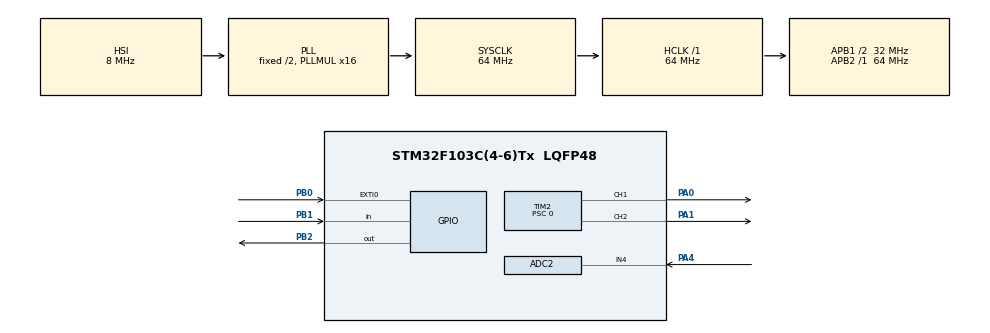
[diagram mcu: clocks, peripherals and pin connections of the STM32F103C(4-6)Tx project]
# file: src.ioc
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ADC1.Channel-2\#ChannelRegularConversion=ADC_CHANNEL_VREFINT
ADC1.ContinuousConvMode=DISABLE
ADC1.DiscontinuousConvMode=DISABLE
ADC1.EnableRegularConversion=ENABLE
ADC1.NbrOfConversion=1
ADC1.NbrOfConversionFlag=1
ADC1.Rank-2\#ChannelRegularConversion=1
ADC1.SamplingTime-2\#ChannelRegularConversion=ADC_SAMPLETIME_7CYCLES_5
ADC1.master=1
ADC2.Channel-1\#ChannelRegularConversion=ADC_CHANNEL_4
ADC2.NbrOfConversionFlag=1
ADC2.Rank-1\#ChannelRegularConversion=1
ADC2.SamplingTime-1\#ChannelRegularConversion=ADC_SAMPLETIME_13CYCLES_5
Dma.Request0=TIM2_CH1
Dma.Request1=TIM2_CH2/CH4
Dma.TIM2_CH1.0.Direction=DMA_MEMORY_TO_PERIPH
Dma.TIM2_CH1.0.Instance=DMA1_Channel5
Dma.TIM2_CH1.0.MemDataAlignment=DMA_MDATAALIGN_WORD
Dma.TIM2_CH1.0.MemInc=DMA_MINC_ENABLE
Dma.TIM2_CH1.0.Mode=DMA_NORMAL
Dma.TIM2_CH1.0.PeriphDataAlignment=DMA_PDATAALIGN_WORD
Dma.TIM2_CH1.0.PeriphInc=DMA_PINC_DISABLE
Dma.TIM2_CH1.0.Priority=DMA_PRIORITY_LOW
Dma.TIM2_CH2/CH4.1.Direction=DMA_MEMORY_TO_PERIPH
Dma.TIM2_CH2/CH4.1.Instance=DMA1_Channel7
Dma.TIM2_CH2/CH4.1.MemDataAlignment=DMA_MDATAALIGN_WORD
Dma.TIM2_CH2/CH4.1.MemInc=DMA_MINC_ENABLE
Dma.TIM2_CH2/CH4.1.Mode=DMA_NORMAL
Dma.TIM2_CH2/CH4.1.PeriphDataAlignment=DMA_PDATAALIGN_WORD
Dma.TIM2_CH2/CH4.1.PeriphInc=DMA_PINC_DISABLE
Dma.TIM2_CH2/CH4.1.Priority=DMA_PRIORITY_LOW
Mcu.Family=STM32F1
Mcu.Name=STM32F103C(4-6)Tx
Mcu.Package=LQFP48
NVIC.DMA1_Channel5_IRQn=true\:0\:0\:false\:false\:true\:false\:true\:true
NVIC.DMA1_Channel7_IRQn=true\:0\:0\:false\:false\:true\:false\:true\:true
NVIC.EXTI0_IRQn=true\:1\:0\:true\:false\:true\:true\:true\:true
NVIC.PriorityGroup=NVIC_PRIORITYGROUP_4
NVIC.TIM1_UP_IRQn=true\:2\:0\:true\:false\:true\:true\:true\:true
NVIC.TIM3_IRQn=true\:0\:0\:false\:false\:true\:true\:true\:true
PA0-WKUP.Signal=S_TIM2_CH1_ETR
PA1.Signal=S_TIM2_CH2
PA13.Mode=Serial_Wire
PA13.Signal=SYS_JTMS-SWDIO
PA14.Mode=Serial_Wire
PA14.Signal=SYS_JTCK-SWCLK
PA4.Signal=ADCx_IN4
PB0.GPIO_ModeDefaultEXTI=GPIO_MODE_IT_RISING_FALLING
PB0.GPIO_PuPd=GPIO_PULLUP
PB0.Signal=GPXTI0
PB1.Signal=GPIO_Input
PB2.Signal=GPIO_Output
PD0-OSC_IN.Mode=HSE-External-Oscillator
PD0-OSC_IN.Signal=RCC_OSC_IN
PD1-OSC_OUT.Mode=HSE-External-Oscillator
PD1-OSC_OUT.Signal=RCC_OSC_OUT
ProjectManager.HeapSize=0x200
ProjectManager.StackSize=0x400
ProjectManager.TargetToolchain=CMake
RCC.ADCPresc=RCC_ADCPCLK2_DIV8
RCC.AHBFreq_Value=64000000
RCC.APB1CLKDivider=RCC_HCLK_DIV2
RCC.APB1Freq_Value=32000000
RCC.APB1TimFreq_Value=64000000
RCC.APB2Freq_Value=64000000
RCC.APB2TimFreq_Value=64000000
RCC.HCLKFreq_Value=64000000
RCC.PLLMUL=RCC_PLL_MUL16
RCC.SYSCLKFreq_VALUE=64000000
RCC.SYSCLKSource=RCC_SYSCLKSOURCE_PLLCLK
RCC.USBFreq_Value=64000000
SH.ADCx_IN4.0=ADC2_IN4,IN4
SH.S_TIM2_CH1_ETR.0=TIM2_CH1,PWM Generation1 CH1
SH.S_TIM2_CH2.0=TIM2_CH2,PWM Generation2 CH2
TIM1.Period=1000
TIM1.Prescaler=64
TIM2.Channel-PWM\ Generation1\ CH1=TIM_CHANNEL_1
TIM2.Channel-PWM\ Generation2\ CH2=TIM_CHANNEL_2
TIM2.Period=89
TIM2.Prescaler=0
TIM3.Period=1000-1
TIM3.Prescaler=180-1
VP_ADC1_Vref_Input.Mode=IN-Vrefint
VP_TIM1_VS_ClockSourceINT.Mode=Internal
VP_TIM2_VS_ClockSourceINT.Mode=Internal
VP_TIM3_VS_ClockSourceINT.Mode=Internal
board=custom

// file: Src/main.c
/* USER CODE BEGIN Header */
#include "colorSwitch.h"
#include "battery.h"
#include "collisionDetection.h"
/* USER CODE END Header */
#include "main.h"

ADC_HandleTypeDef hadc1;
ADC_HandleTypeDef hadc2;

TIM_HandleTypeDef htim1;
TIM_HandleTypeDef htim2;
TIM_HandleTypeDef htim3;
DMA_HandleTypeDef hdma_tim2_ch1;
DMA_HandleTypeDef hdma_tim2_ch2_ch4;

/* USER CODE BEGIN PV */
extern enum Color_enum ledcolor;
/* USER CODE END PV */

void SystemClock_Config(void);
static void MX_GPIO_Init(void);
static void MX_DMA_Init(void);
static void MX_ADC1_Init(void);
static void MX_TIM2_Init(void);
static void MX_TIM3_Init(void);
static void MX_ADC2_Init(void);
static void MX_TIM1_Init(void);

/* USER CODE BEGIN 0 */
void HAL_GPIO_EXTI_Callback(uint16_t GPIO_Pin){
  if (GPIO_Pin == GPIO_PIN_0) {
    handleColorSwitch();
  }
}

void HAL_TIM_PeriodElapsedCallback(TIM_HandleTypeDef *htim){
  if (htim == &htim3) {
    handleBatteryMonitor();
  }
  if (htim == &htim1) {
    handleDetection();
  }
}
/* USER CODE END 0 */

int main(void)
{

  /* MCU Configuration--------------------------------------------------------*/

  /* Reset of all peripherals, Initializes the Flash interface and the Systick. */
  HAL_Init();

  /* Configure the system clock */
  SystemClock_Config();

  /* Initialize all configured peripherals */
  MX_GPIO_Init();
  MX_DMA_Init();
  MX_ADC1_Init();
  MX_TIM2_Init();
  MX_TIM3_Init();
  MX_ADC2_Init();
  MX_TIM1_Init();
  /* USER CODE BEGIN 2 */
  startCollisionDetection(); //启用碰撞监测
  startBatteryMonitor(); //启用电池电压监测
  /* USER CODE END 2 */

  /* Infinite loop */
  while (1)
  {
  }

}

void SystemClock_Config(void)
{
  RCC_OscInitTypeDef RCC_OscInitStruct = {0};
  RCC_ClkInitTypeDef RCC_ClkInitStruct = {0};
  RCC_PeriphCLKInitTypeDef PeriphClkInit = {0};

  /** Initializes the RCC Oscillators according to the specified parameters
  * in the RCC_OscInitTypeDef structure.
  */
  RCC_OscInitStruct.OscillatorType = RCC_OSCILLATORTYPE_HSI;
  RCC_OscInitStruct.HSIState = RCC_HSI_ON;
  RCC_OscInitStruct.HSICalibrationValue = RCC_HSICALIBRATION_DEFAULT;
  RCC_OscInitStruct.PLL.PLLState = RCC_PLL_ON;
  RCC_OscInitStruct.PLL.PLLSource = RCC_PLLSOURCE_HSI_DIV2;
  RCC_OscInitStruct.PLL.PLLMUL = RCC_PLL_MUL16;
  if (HAL_RCC_OscConfig(&RCC_OscInitStruct) != HAL_OK)
  {
    Error_Handler();
  }

  /** Initializes the CPU, AHB and APB buses clocks
  */
  RCC_ClkInitStruct.ClockType = RCC_CLOCKTYPE_HCLK|RCC_CLOCKTYPE_SYSCLK
                              |RCC_CLOCKTYPE_PCLK1|RCC_CLOCKTYPE_PCLK2;
  RCC_ClkInitStruct.SYSCLKSource = RCC_SYSCLKSOURCE_PLLCLK;
  RCC_ClkInitStruct.AHBCLKDivider = RCC_SYSCLK_DIV1;
  RCC_ClkInitStruct.APB1CLKDivider = RCC_HCLK_DIV2;
  RCC_ClkInitStruct.APB2CLKDivider = RCC_HCLK_DIV1;

  if (HAL_RCC_ClockConfig(&RCC_ClkInitStruct, FLASH_LATENCY_2) != HAL_OK)
  {
    Error_Handler();
  }
  PeriphClkInit.PeriphClockSelection = RCC_PERIPHCLK_ADC;
  PeriphClkInit.AdcClockSelection = RCC_ADCPCLK2_DIV8;
  if (HAL_RCCEx_PeriphCLKConfig(&PeriphClkInit) != HAL_OK)
  {
    Error_Handler();
  }
}

static void MX_ADC1_Init(void)
{

  ADC_ChannelConfTypeDef sConfig = {0};

  /** Common config
  */
  hadc1.Instance = ADC1;
  hadc1.Init.ScanConvMode = ADC_SCAN_DISABLE;
  hadc1.Init.ContinuousConvMode = DISABLE;
  hadc1.Init.DiscontinuousConvMode = DISABLE;
  hadc1.Init.ExternalTrigConv = ADC_SOFTWARE_START;
  hadc1.Init.DataAlign = ADC_DATAALIGN_RIGHT;
  hadc1.Init.NbrOfConversion = 1;
  if (HAL_ADC_Init(&hadc1) != HAL_OK)
  {
    Error_Handler();
  }

  /** Configure Regular Channel
  */
  sConfig.Channel = ADC_CHANNEL_VREFINT;
  sConfig.Rank = ADC_REGULAR_RANK_1;
  sConfig.SamplingTime = ADC_SAMPLETIME_7CYCLES_5;
  if (HAL_ADC_ConfigChannel(&hadc1, &sConfig) != HAL_OK)
  {
    Error_Handler();
  }

}

static void MX_ADC2_Init(void)
{

  ADC_ChannelConfTypeDef sConfig = {0};

  /** Common config
  */
  hadc2.Instance = ADC2;
  hadc2.Init.ScanConvMode = ADC_SCAN_DISABLE;
  hadc2.Init.ContinuousConvMode = DISABLE;
  hadc2.Init.DiscontinuousConvMode = DISABLE;
  hadc2.Init.ExternalTrigConv = ADC_SOFTWARE_START;
  hadc2.Init.DataAlign = ADC_DATAALIGN_RIGHT;
  hadc2.Init.NbrOfConversion = 1;
  if (HAL_ADC_Init(&hadc2) != HAL_OK)
  {
    Error_Handler();
  }

  /** Configure Regular Channel
  */
  sConfig.Channel = ADC_CHANNEL_4;
  sConfig.Rank = ADC_REGULAR_RANK_1;
  sConfig.SamplingTime = ADC_SAMPLETIME_13CYCLES_5;
  if (HAL_ADC_ConfigChannel(&hadc2, &sConfig) != HAL_OK)
  {
    Error_Handler();
  }

}

static void MX_TIM1_Init(void)
{

  TIM_ClockConfigTypeDef sClockSourceConfig = {0};
  TIM_MasterConfigTypeDef sMasterConfig = {0};

  htim1.Instance = TIM1;
  htim1.Init.Prescaler = 64;
  htim1.Init.CounterMode = TIM_COUNTERMODE_UP;
  htim1.Init.Period = 1000;
  htim1.Init.ClockDivision = TIM_CLOCKDIVISION_DIV1;
  htim1.Init.RepetitionCounter = 0;
  htim1.Init.AutoReloadPreload = TIM_AUTORELOAD_PRELOAD_DISABLE;
  if (HAL_TIM_Base_Init(&htim1) != HAL_OK)
  {
    Error_Handler();
  }
  sClockSourceConfig.ClockSource = TIM_CLOCKSOURCE_INTERNAL;
  if (HAL_TIM_ConfigClockSource(&htim1, &sClockSourceConfig) != HAL_OK)
  {
    Error_Handler();
  }
  sMasterConfig.MasterOutputTrigger = TIM_TRGO_RESET;
  sMasterConfig.MasterSlaveMode = TIM_MASTERSLAVEMODE_DISABLE;
  if (HAL_TIMEx_MasterConfigSynchronization(&htim1, &sMasterConfig) != HAL_OK)
  {
    Error_Handler();
  }

}

static void MX_TIM2_Init(void)
{

  TIM_ClockConfigTypeDef sClockSourceConfig = {0};
  TIM_MasterConfigTypeDef sMasterConfig = {0};
  TIM_OC_InitTypeDef sConfigOC = {0};

  htim2.Instance = TIM2;
  htim2.Init.Prescaler = 0;
  htim2.Init.CounterMode = TIM_COUNTERMODE_UP;
  htim2.Init.Period = 89;
  htim2.Init.ClockDivision = TIM_CLOCKDIVISION_DIV1;
  htim2.Init.AutoReloadPreload = TIM_AUTORELOAD_PRELOAD_DISABLE;
  if (HAL_TIM_Base_Init(&htim2) != HAL_OK)
  {
    Error_Handler();
  }
  sClockSourceConfig.ClockSource = TIM_CLOCKSOURCE_INTERNAL;
  if (HAL_TIM_ConfigClockSource(&htim2, &sClockSourceConfig) != HAL_OK)
  {
    Error_Handler();
  }
  if (HAL_TIM_PWM_Init(&htim2) != HAL_OK)
  {
    Error_Handler();
  }
  sMasterConfig.MasterOutputTrigger = TIM_TRGO_RESET;
  sMasterConfig.MasterSlaveMode = TIM_MASTERSLAVEMODE_DISABLE;
  if (HAL_TIMEx_MasterConfigSynchronization(&htim2, &sMasterConfig) != HAL_OK)
  {
    Error_Handler();
  }
  sConfigOC.OCMode = TIM_OCMODE_PWM1;
  sConfigOC.Pulse = 0;
  sConfigOC.OCPolarity = TIM_OCPOLARITY_HIGH;
  sConfigOC.OCFastMode = TIM_OCFAST_DISABLE;
  if (HAL_TIM_PWM_ConfigChannel(&htim2, &sConfigOC, TIM_CHANNEL_1) != HAL_OK)
  {
    Error_Handler();
  }
  if (HAL_TIM_PWM_ConfigChannel(&htim2, &sConfigOC, TIM_CHANNEL_2) != HAL_OK)
  {
    Error_Handler();
  }
  HAL_TIM_MspPostInit(&htim2);

}

static void MX_TIM3_Init(void)
{

  TIM_ClockConfigTypeDef sClockSourceConfig = {0};
  TIM_MasterConfigTypeDef sMasterConfig = {0};

  htim3.Instance = TIM3;
  htim3.Init.Prescaler = 180-1;
  htim3.Init.CounterMode = TIM_COUNTERMODE_UP;
  htim3.Init.Period = 1000-1;
  htim3.Init.ClockDivision = TIM_CLOCKDIVISION_DIV1;
  htim3.Init.AutoReloadPreload = TIM_AUTORELOAD_PRELOAD_DISABLE;
  if (HAL_TIM_Base_Init(&htim3) != HAL_OK)
  {
    Error_Handler();
  }
  sClockSourceConfig.ClockSource = TIM_CLOCKSOURCE_INTERNAL;
  if (HAL_TIM_ConfigClockSource(&htim3, &sClockSourceConfig) != HAL_OK)
  {
    Error_Handler();
  }
  sMasterConfig.MasterOutputTrigger = TIM_TRGO_RESET;
  sMasterConfig.MasterSlaveMode = TIM_MASTERSLAVEMODE_DISABLE;
  if (HAL_TIMEx_MasterConfigSynchronization(&htim3, &sMasterConfig) != HAL_OK)
  {
    Error_Handler();
  }

}

static void MX_DMA_Init(void)
{

  /* DMA controller clock enable */
  __HAL_RCC_DMA1_CLK_ENABLE();

  /* DMA interrupt init */
  /* DMA1_Channel5_IRQn interrupt configuration */
  HAL_NVIC_SetPriority(DMA1_Channel5_IRQn, 0, 0);
  HAL_NVIC_EnableIRQ(DMA1_Channel5_IRQn);
  /* DMA1_Channel7_IRQn interrupt configuration */
  HAL_NVIC_SetPriority(DMA1_Channel7_IRQn, 0, 0);
  HAL_NVIC_EnableIRQ(DMA1_Channel7_IRQn);

}

static void MX_GPIO_Init(void)
{
  GPIO_InitTypeDef GPIO_InitStruct = {0};

  /* GPIO Ports Clock Enable */
  __HAL_RCC_GPIOD_CLK_ENABLE();
  __HAL_RCC_GPIOA_CLK_ENABLE();
  __HAL_RCC_GPIOB_CLK_ENABLE();

  /*Configure GPIO pin Output Level */
  HAL_GPIO_WritePin(GPIOB, GPIO_PIN_2, GPIO_PIN_RESET);

  /*Configure GPIO pin : PB0 */
  GPIO_InitStruct.Pin = GPIO_PIN_0;
  GPIO_InitStruct.Mode = GPIO_MODE_IT_RISING_FALLING;
  GPIO_InitStruct.Pull = GPIO_PULLUP;
  HAL_GPIO_Init(GPIOB, &GPIO_InitStruct);

  /*Configure GPIO pin : PB1 */
  GPIO_InitStruct.Pin = GPIO_PIN_1;
  GPIO_InitStruct.Mode = GPIO_MODE_INPUT;
  GPIO_InitStruct.Pull = GPIO_NOPULL;
  HAL_GPIO_Init(GPIOB, &GPIO_InitStruct);

  /*Configure GPIO pin : PB2 */
  GPIO_InitStruct.Pin = GPIO_PIN_2;
  GPIO_InitStruct.Mode = GPIO_MODE_OUTPUT_PP;
  GPIO_InitStruct.Pull = GPIO_NOPULL;
  GPIO_InitStruct.Speed = GPIO_SPEED_FREQ_LOW;
  HAL_GPIO_Init(GPIOB, &GPIO_InitStruct);

  /* EXTI interrupt init*/
  HAL_NVIC_SetPriority(EXTI0_IRQn, 1, 0);
  HAL_NVIC_EnableIRQ(EXTI0_IRQn);

}

void Error_Handler(void)
{
  __disable_irq();
  while (1)
  {
  }
}
